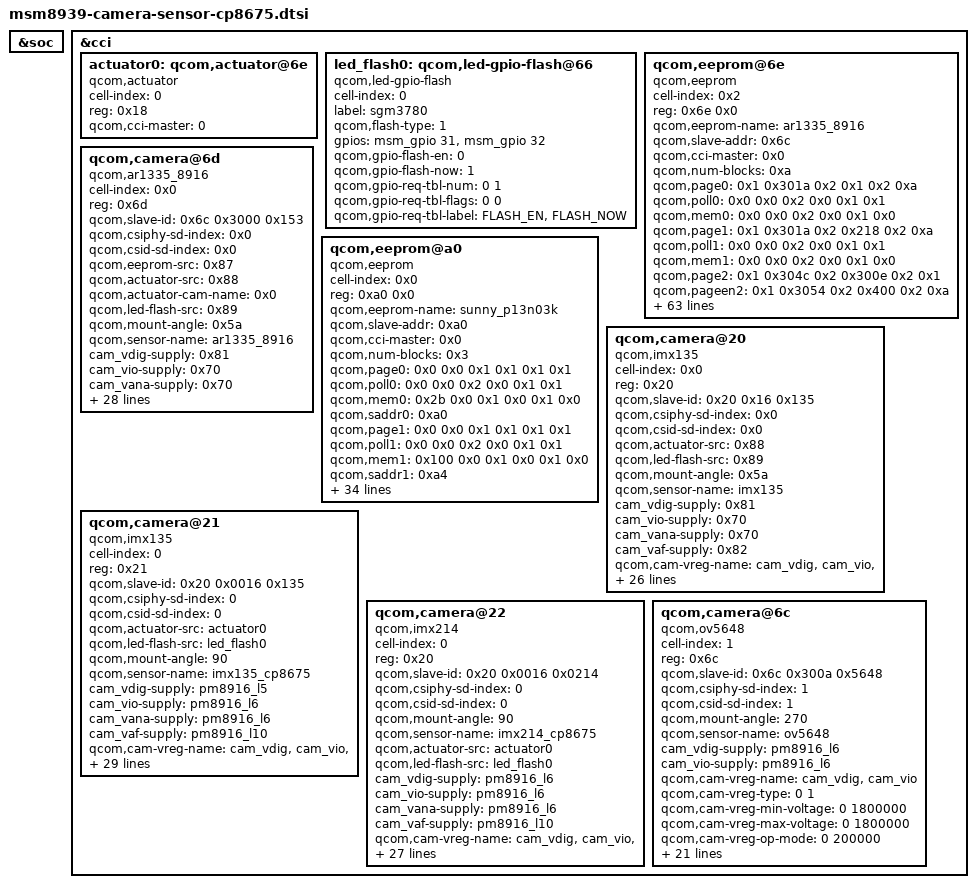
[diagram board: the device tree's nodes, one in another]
/*
 * Copyright (c) 2014, The Linux Foundation. All rights reserved.
 *
 * This program is free software; you can redistribute it and/or modify
 * it under the terms of the GNU General Public License version 2 and
 * only version 2 as published by the Free Software Foundation.
 *
 * This program is distributed in the hope that it will be useful,
 * but WITHOUT ANY WARRANTY; without even the implied warranty of
 * MERCHANTABILITY or FITNESS FOR A PARTICULAR PURPOSE.  See the
 * GNU General Public License for more details.
 */

&soc {
};

&cci {
	actuator0: qcom,actuator@6e {
		cell-index = <0>;
		reg = <0x18>;
		compatible = "qcom,actuator";
		qcom,cci-master = <0>;
	};

	led_flash0: qcom,led-gpio-flash@66 {
		cell-index = <0>;
		compatible = "qcom,led-gpio-flash";
		label = "sgm3780";
		qcom,flash-type = <1>;
		gpios = <&msm_gpio 31 0>,
			<&msm_gpio 32 0>;
		qcom,gpio-flash-en = <0>;
		qcom,gpio-flash-now = <1>;
		qcom,gpio-req-tbl-num = <0 1>;
		qcom,gpio-req-tbl-flags = <0 0>;
		qcom,gpio-req-tbl-label = "FLASH_EN",
			"FLASH_NOW";
	};

	qcom,eeprom@6e {
		cell-index = <0x2>;
		reg = <0x6e 0x0>;
		qcom,eeprom-name = "ar1335_8916";
		compatible = "qcom,eeprom";
		qcom,slave-addr = <0x6c>;
		qcom,cci-master = <0x0>;
		qcom,num-blocks = <0xa>;
		qcom,page0 = <0x1 0x301a 0x2 0x1 0x2 0xa>;
		qcom,poll0 = <0x0 0x0 0x2 0x0 0x1 0x1>;
		qcom,mem0 = <0x0 0x0 0x2 0x0 0x1 0x0>;
		qcom,page1 = <0x1 0x301a 0x2 0x218 0x2 0xa>;
		qcom,poll1 = <0x0 0x0 0x2 0x0 0x1 0x1>;
		qcom,mem1 = <0x0 0x0 0x2 0x0 0x1 0x0>;
		qcom,page2 = <0x1 0x304c 0x2 0x300e 0x2 0x1>;
		qcom,pageen2 = <0x1 0x3054 0x2 0x400 0x2 0xa>;
		qcom,poll2 = <0x0 0x0 0x2 0x0 0x1 0x1>;
		qcom,mem2 = <0x0 0x0 0x2 0x0 0x1 0x0>;
		qcom,page3 = <0x1 0x304a 0x2 0x210 0x2 0x14>;
		qcom,poll3 = <0x1 0x304a 0x2 0x270 0x2 0x1>;
		qcom,mem3 = <0x1c 0x3800 0x2 0x0 0x1 0x0>;
		qcom,page4 = <0x1 0x304c 0x2 0x3706 0x2 0x1>;
		qcom,pageen4 = <0x1 0x3054 0x2 0x400 0x2 0xa>;
		qcom,poll4 = <0x0 0x0 0x2 0x0 0x1 0x1>;
		qcom,mem4 = <0x0 0x0 0x2 0x0 0x1 0x0>;
		qcom,page5 = <0x1 0x304a 0x2 0x210 0x2 0x14>;
		qcom,poll5 = <0x1 0x304a 0x2 0x270 0x2 0x1>;
		qcom,mem5 = <0xc 0x3800 0x2 0x0 0x1 0x0>;
		qcom,page6 = <0x1 0x304c 0x2 0x3806 0x2 0x1>;
		qcom,pageen6 = <0x1 0x3054 0x2 0x400 0x2 0xa>;
		qcom,poll6 = <0x0 0x0 0x2 0x0 0x1 0x1>;
		qcom,mem6 = <0x0 0x0 0x2 0x0 0x1 0x0>;
		qcom,page7 = <0x1 0x304a 0x2 0x210 0x2 0x14>;
		qcom,poll7 = <0x1 0x304a 0x2 0x270 0x2 0x1>;
		qcom,mem7 = <0xc 0x3800 0x2 0x0 0x1 0x0>;
		qcom,page8 = <0x1 0x304c 0x2 0x3906 0x2 0x1>;
		qcom,pageen8 = <0x1 0x3054 0x2 0x400 0x2 0xa>;
		qcom,poll8 = <0x0 0x0 0x2 0x0 0x1 0x1>;
		qcom,mem8 = <0x0 0x0 0x2 0x0 0x1 0x0>;
		qcom,page9 = <0x1 0x304a 0x2 0x210 0x2 0x14>;
		qcom,poll9 = <0x1 0x304a 0x2 0x270 0x2 0x1>;
		qcom,mem9 = <0xc 0x3800 0x2 0x0 0x1 0x0>;
		cam_vdig-supply = <0x81>;
		cam_vio-supply = <0x70>;
		cam_vana-supply = <0x70>;
		cam_vaf-supply = <0x82>;
		qcom,cam-vreg-name = "cam_vdig", "cam_vio", "cam_vana", "cam_vaf";
		qcom,cam-vreg-min-voltage = <0x1b7740 0x1b7740 0x1b7740 0x2ab980>;
		qcom,cam-vreg-max-voltage = <0x1b7740 0x1b7740 0x1b7740 0x2ab980>;
		qcom,cam-vreg-op-mode = <0x30d40 0x0 0x13880 0x186a0>;
		pinctrl-names = "cam_default", "cam_suspend";
		pinctrl-0 = <0x83 0x84>;
		pinctrl-1 = <0x85 0x86>;
		qcom,gpio-no-mux = <0x0>;
		gpios = <0x77 0x1a 0x0 0x77 0x22 0x0 0x77 0x77 0x0 0x77 0x78 0x0 0x77 0x10 0x0>;
		qcom,gpio-standby = <0x1>;
		qcom,gpio-vana = <0x2>;
		qcom,gpio-vdig = <0x3>;
		qcom,gpio-af-pwdm = <0x4>;
		qcom,gpio-req-tbl-num = <0x0 0x1 0x2 0x3 0x4>;
		qcom,gpio-req-tbl-flags = <0x1 0x0 0x0 0x0 0x0>;
		qcom,gpio-req-tbl-label = "CAMIF_MCLK", "CAM_STANDBY", "CAM_VANA", "CAM_VDIG", "CAM_AF_PWDM";
		qcom,cam-power-seq-type = "sensor_gpio", "sensor_vreg", "sensor_gpio", "sensor_gpio", "sensor_vreg", "sensor_clk", "sensor_gpio";
		qcom,cam-power-seq-val = "sensor_gpio_standby", "cam_vio", "sensor_gpio_vana", "sensor_gpio_vdig", "cam_vaf", "sensor_cam_mclk", "sensor_gpio_standby";
		qcom,cam-power-seq-cfg-val = <0x0 0x1 0x1 0x1 0x1 0x16e3600 0x1>;
		qcom,cam-power-seq-delay = <0xa 0xa 0xa 0xa 0xa 0xa 0xa>;
		clocks = <0x1b 0x266b3853 0x1b 0x80902deb>;
		clock-names = "cam_src_clk", "cam_clk";
		linux,phandle = <0x87>;
		phandle = <0x87>;
	};

	qcom,camera@6d {
		cell-index = <0x0>;
		compatible = "qcom,ar1335_8916";
		reg = <0x6d>;
		qcom,slave-id = <0x6c 0x3000 0x153>;
		qcom,csiphy-sd-index = <0x0>;
		qcom,csid-sd-index = <0x0>;
		qcom,eeprom-src = <0x87>;
		qcom,actuator-src = <0x88>;
		qcom,actuator-cam-name = <0x0>;
		qcom,led-flash-src = <0x89>;
		qcom,mount-angle = <0x5a>;
		qcom,sensor-name = "ar1335_8916";
		cam_vdig-supply = <0x81>;
		cam_vio-supply = <0x70>;
		cam_vana-supply = <0x70>;
		cam_vaf-supply = <0x82>;
		qcom,cam-vreg-name = "cam_vdig", "cam_vio", "cam_vana", "cam_vaf";
		qcom,cam-vreg-min-voltage = <0x1b7740 0x1b7740 0x1b7740 0x2ab980>;
		qcom,cam-vreg-max-voltage = <0x1b7740 0x1b7740 0x1b7740 0x2ab980>;
		qcom,cam-vreg-op-mode = <0x30d40 0x0 0x13880 0x186a0>;
		pinctrl-names = "cam_default", "cam_suspend";
		pinctrl-0 = <0x83 0x84>;
		pinctrl-1 = <0x85 0x86>;
		qcom,gpio-no-mux = <0x0>;
		gpios = <0x77 0x1a 0x0 0x77 0x22 0x0 0x77 0x77 0x0 0x77 0x78 0x0 0x77 0x10 0x0>;
		qcom,gpio-standby = <0x1>;
		qcom,gpio-vana = <0x2>;
		qcom,gpio-vdig = <0x3>;
		qcom,gpio-af-pwdm = <0x4>;
		qcom,gpio-req-tbl-num = <0x0 0x1 0x2 0x3 0x4>;
		qcom,gpio-req-tbl-flags = <0x1 0x0 0x0 0x0 0x0>;
		qcom,gpio-req-tbl-label = "CAMIF_MCLK", "CAM_STANDBY", "CAM_VANA", "CAM_VDIG", "CAM_AF_PWDM";
		qcom,csi-lane-assign = <0x4320>;
		qcom,csi-lane-mask = <0x1f>;
		qcom,sensor-position = <0x0>;
		qcom,sensor-mode = <0x1>;
		qcom,cci-master = <0x0>;
		status = "ok";
		clocks = <0x1b 0x266b3853 0x1b 0x80902deb>;
		clock-names = "cam_src_clk", "cam_clk";
	};

	qcom,eeprom@a0 {
		cell-index = <0x0>;
		reg = <0xa0 0x0>;
		qcom,eeprom-name = "sunny_p13n03k";
		compatible = "qcom,eeprom";
		qcom,slave-addr = <0xa0>;
		qcom,cci-master = <0x0>;
		qcom,num-blocks = <0x3>;
		qcom,page0 = <0x0 0x0 0x1 0x1 0x1 0x1>;
		qcom,poll0 = <0x0 0x0 0x2 0x0 0x1 0x1>;
		qcom,mem0 = <0x2b 0x0 0x1 0x0 0x1 0x0>;
		qcom,saddr0 = <0xa0>;
		qcom,page1 = <0x0 0x0 0x1 0x1 0x1 0x1>;
		qcom,poll1 = <0x0 0x0 0x2 0x0 0x1 0x1>;
		qcom,mem1 = <0x100 0x0 0x1 0x0 0x1 0x0>;
		qcom,saddr1 = <0xa4>;
		qcom,page2 = <0x0 0x0 0x1 0x1 0x1 0x1>;
		qcom,poll2 = <0x0 0x0 0x2 0x0 0x1 0x1>;
		qcom,mem2 = <0xfb 0x0 0x1 0x0 0x1 0x0>;
		qcom,saddr2 = <0xa6>;
		cam_vdig-supply = <0x81>;
		cam_vio-supply = <0x70>;
		cam_vana-supply = <0x70>;
		cam_vaf-supply = <0x82>;
		qcom,cam-vreg-name = "cam_vdig", "cam_vio", "cam_vana", "cam_vaf";
		qcom,cam-vreg-min-voltage = <0x1b7740 0x1b7740 0x1b7740 0x2ab980>;
		qcom,cam-vreg-max-voltage = <0x1b7740 0x1b7740 0x1b7740 0x2ab980>;
		qcom,cam-vreg-op-mode = <0x30d40 0x0 0x13880 0x186a0>;
		qcom,gpio-no-mux = <0x0>;
		gpios = <0x77 0x1a 0x0 0x77 0x22 0x0 0x77 0x77 0x0 0x77 0x78 0x0 0x77 0x10 0x0>;
		qcom,gpio-standby = <0x1>;
		qcom,gpio-vana = <0x2>;
		qcom,gpio-vdig = <0x3>;
		qcom,gpio-af-pwdm = <0x4>;
		qcom,gpio-req-tbl-num = <0x0 0x1 0x2 0x3 0x4>;
		qcom,gpio-req-tbl-flags = <0x1 0x0 0x0 0x0 0x0>;
		qcom,gpio-req-tbl-label = "CAMIF_MCLK", "CAM_STANDBY", "CAM_VANA", "CAM_VDIG", "CAM_AF_PWDM";
		qcom,cam-power-seq-type = "sensor_vreg", "sensor_vreg", "sensor_clk", "sensor_gpio";
		qcom,cam-power-seq-val = "cam_vdig", "cam_vio", "sensor_cam_mclk", "sensor_gpio_reset";
		qcom,cam-power-seq-cfg-val = <0x1 0x1 0x16e3600 0x1>;
		qcom,cam-power-seq-delay = <0x1 0x1 0x5 0x5>;
	};

	qcom,camera@20 {
		cell-index = <0x0>;
		compatible = "qcom,imx135";
		reg = <0x20>;
		qcom,slave-id = <0x20 0x16 0x135>;
		qcom,csiphy-sd-index = <0x0>;
		qcom,csid-sd-index = <0x0>;
		qcom,actuator-src = <0x88>;
		qcom,led-flash-src = <0x89>;
		qcom,mount-angle = <0x5a>;
		qcom,sensor-name = "imx135";
		cam_vdig-supply = <0x81>;
		cam_vio-supply = <0x70>;
		cam_vana-supply = <0x70>;
		cam_vaf-supply = <0x82>;
		qcom,cam-vreg-name = "cam_vdig", "cam_vio", "cam_vana", "cam_vaf";
		qcom,cam-vreg-min-voltage = <0x1b7740 0x1b7740 0x1b7740 0x2ab980>;
		qcom,cam-vreg-max-voltage = <0x1b7740 0x1b7740 0x1b7740 0x2ab980>;
		qcom,cam-vreg-op-mode = <0x30d40 0x0 0x13880 0x186a0>;
		pinctrl-names = "cam_default", "cam_suspend";
		pinctrl-0 = <0x83 0x84>;
		pinctrl-1 = <0x85 0x86>;
		qcom,gpio-no-mux = <0x0>;
		gpios = <0x77 0x1a 0x0 0x77 0x22 0x0 0x77 0x77 0x0 0x77 0x78 0x0 0x77 0x10 0x0>;
		qcom,gpio-standby = <0x1>;
		qcom,gpio-vana = <0x2>;
		qcom,gpio-vdig = <0x3>;
		qcom,gpio-af-pwdm = <0x4>;
		qcom,gpio-req-tbl-num = <0x0 0x1 0x2 0x3 0x4>;
		qcom,gpio-req-tbl-flags = <0x1 0x0 0x0 0x0 0x0>;
		qcom,gpio-req-tbl-label = "CAMIF_MCLK", "CAM_STANDBY", "CAM_VANA", "CAM_VDIG", "CAM_AF_PWDM";
		qcom,csi-lane-assign = <0x4320>;
		qcom,csi-lane-mask = <0x1f>;
		qcom,sensor-position = <0x0>;
		qcom,sensor-mode = <0x1>;
		qcom,cci-master = <0x0>;
		status = "ok";
		clocks = <0x1b 0x266b3853 0x1b 0x80902deb>;
		clock-names = "cam_src_clk", "cam_clk";
	};

	qcom,camera@21 {
		cell-index = <0>;
		compatible = "qcom,imx135", "qcom,camera";
		reg = <0x21>;
		qcom,slave-id = <0x20 0x0016 0x135>;
		qcom,csiphy-sd-index = <0>;
		qcom,csid-sd-index = <0>;
		qcom,actuator-src = <&actuator0>;
		qcom,led-flash-src = <&led_flash0>;
		qcom,mount-angle = <90>;
		qcom,sensor-name = "imx135_cp8675";
		cam_vdig-supply = <&pm8916_l5>;
		cam_vio-supply = <&pm8916_l6>;
		cam_vana-supply = <&pm8916_l6>;
		cam_vaf-supply = <&pm8916_l10>;
		qcom,cam-vreg-name = "cam_vdig", "cam_vio", "cam_vana",
			"cam_vaf";
		qcom,cam-vreg-type = <0 1 0 0>;
		qcom,cam-vreg-min-voltage = <1800000 1800000 1800000 2800000>;
		qcom,cam-vreg-max-voltage = <1800000 1800000 1800000 2800000>;
		qcom,cam-vreg-op-mode = <200000 0 80000 100000>;
		pinctrl-names = "cam_default", "cam_suspend";
		pinctrl-0 = <&cam_sensor_mclk0_default
			&cam_sensor_rear_default>;
		pinctrl-1 = <&cam_sensor_mclk0_sleep &cam_sensor_rear_sleep>;
		qcom,gpio-no-mux = <0>;
		gpios = <&msm_gpio 26 0>,
			<&msm_gpio 16 0>,
			<&msm_gpio 119 0>,
			<&msm_gpio 120 0>,
			<&msm_gpio 34 0>;
		qcom,gpio-standby = <1>;
		qcom,gpio-vana = <2>;
		qcom,gpio-vdig = <3>;
		qcom,gpio-af-pwdm = <4>;
		qcom,gpio-req-tbl-num = <0 1 2 3 4>;
		qcom,gpio-req-tbl-flags = <1 0 0 0 0>;
		qcom,gpio-req-tbl-label = "CAMIF_MCLK",
			"CAM_STANDBY",
			"CAM_VANA",
			"CAM_VDIG",
			"CAM_AF_PWDM";
		qcom,csi-lane-assign = <0x4320>;
		qcom,csi-lane-mask = <0x1f>;
		qcom,sensor-position = <0>;
		qcom,sensor-mode = <1>;
		qcom,cci-master = <0>;
		status = "ok";
		clocks = <&clock_gcc clk_mclk0_clk_src>,
			<&clock_gcc clk_gcc_camss_mclk0_clk>;
		clock-names = "cam_src_clk", "cam_clk";
	};

	qcom,camera@22 {
		cell-index = <0>;
		compatible = "qcom,imx214", "qcom,camera";
		reg = <0x20>;
		qcom,slave-id = <0x20 0x0016 0x0214>;
		qcom,csiphy-sd-index = <0>;
		qcom,csid-sd-index = <0>;
		qcom,mount-angle = <90>;
		qcom,sensor-name = "imx214_cp8675";
		qcom,actuator-src = <&actuator0>;
		qcom,led-flash-src = <&led_flash0>;
		cam_vdig-supply = <&pm8916_l6>;
		cam_vio-supply = <&pm8916_l6>;
		cam_vana-supply = <&pm8916_l6>;
		cam_vaf-supply = <&pm8916_l10>;
		qcom,cam-vreg-name = "cam_vdig", "cam_vio", "cam_vana","cam_vaf";
		qcom,cam-vreg-type = <0 0 0 0>;
		qcom,cam-vreg-min-voltage = <0 1800000 0 2800000>;
		qcom,cam-vreg-max-voltage = <0 1800000 0 2800000>;
		qcom,cam-vreg-op-mode = <0 105000 0 100000>;
		pinctrl-names = "cam_default", "cam_suspend";
		pinctrl-0 = <&cam_sensor_mclk0_default &cam_sensor_rear_default>;
		pinctrl-1 = <&cam_sensor_mclk0_sleep &cam_sensor_rear_sleep>;
		qcom,gpio-no-mux = <0>;
		gpios = <&msm_gpio 26 0>,
			<&msm_gpio 16 0>,
			<&msm_gpio 119 0>,
			<&msm_gpio 120 0>,
			<&msm_gpio 34 0>;
		qcom,gpio-standby = <1>;
		qcom,gpio-vana = <2>;
		qcom,gpio-vdig = <3>;
		qcom,gpio-af-pwdm = <4>;
		qcom,gpio-req-tbl-num = <0 1 2 3 4>;
		qcom,gpio-req-tbl-flags = <1 0 0 0 0>;
		qcom,gpio-req-tbl-label = "CAMIF_MCLK",
			"CAM_STANDBY",
			"CAM_VANA",
			"CAM_VDIG",
			"CAM_AF_PWDM";
		qcom,csi-lane-assign = <0x4320>;
		qcom,csi-lane-mask = <0x1f>;
		qcom,sensor-position = <0>;
		qcom,sensor-mode = <1>;
		qcom,cci-master = <0>;
		status = "ok";
		clocks = <&clock_gcc clk_mclk0_clk_src>,
			<&clock_gcc clk_gcc_camss_mclk0_clk>;
		clock-names = "cam_src_clk", "cam_clk";
	};

	qcom,camera@6c {
		cell-index = <1>;
		compatible = "qcom,ov5648";
		reg = <0x6c>;
		qcom,slave-id = <0x6c 0x300a 0x5648>;
		qcom,csiphy-sd-index = <1>;
		qcom,csid-sd-index = <1>;
		qcom,mount-angle = <270>;
		qcom,sensor-name = "ov5648";
		cam_vdig-supply = <&pm8916_l6>;
		cam_vio-supply = <&pm8916_l6>;
		qcom,cam-vreg-name = "cam_vdig", "cam_vio";
		qcom,cam-vreg-type = <0 1>;
		qcom,cam-vreg-min-voltage = <0 1800000>;
		qcom,cam-vreg-max-voltage = <0 1800000>;
		qcom,cam-vreg-op-mode = <0 200000>;
		pinctrl-names = "cam_default", "cam_suspend";
		pinctrl-0 = <&cam_sensor_mclk1_default
			&cam_sensor_front_default>;
		pinctrl-1 = <&cam_sensor_mclk1_sleep &cam_sensor_front_sleep>;
		qcom,gpio-no-mux = <0>;
		gpios = <&msm_gpio 27 0>,
			<&msm_gpio 28 0>,
			<&msm_gpio 33 0>,
			<&msm_gpio 119 0>;
		qcom,gpio-reset = <1>;
		qcom,gpio-standby = <2>;
		qcom,gpio-vana = <3>;
		qcom,gpio-req-tbl-num = <0 1 2 3>;
		qcom,gpio-req-tbl-flags = <1 0 0 0>;
		qcom,gpio-req-tbl-label = "CAMIF_MCLK",
			"CAM_RESET",
			"CAM_STANDBY",
			"CAM_VANA";
		qcom,csi-lane-assign = <0x4320>;
		qcom,csi-lane-mask = <0x07>;
		qcom,sensor-position = <1>;
		qcom,sensor-mode = <0>;
		qcom,cci-master = <0>;
		status = "ok";
		clocks = <&clock_gcc clk_mclk1_clk_src>,
			<&clock_gcc clk_gcc_camss_mclk1_clk>;
		clock-names = "cam_src_clk", "cam_clk";
	};
};
